# RE01_256KB register map
Vendor: Renesas Electronics Corporation; Series: RE01; File version: 1.00.01
CPU: CM0PLUS r0p1, little endian, MPU, no FPU, VTOR, 2 interrupt priority bits, 32 interrupts
Registers are 8-bit, read-write, reset 0x0 unless marked. A register's access mark holds for its fields unless they carry their own. Offsets are from the block's base; [hi:lo] are bit positions; 'fields as' and 'values as' point back to an identical list.

## MMF — Memory Mirror Function
Base 0x40001000
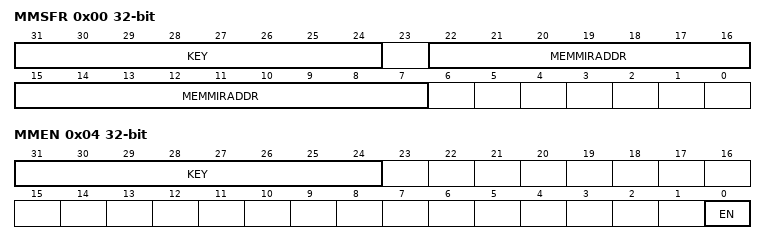
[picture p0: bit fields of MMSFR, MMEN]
0x00 MMSFR 32-bit — MemMirror Special Function Register
  [31:24] KEY wo — MMSFR Key Code
  [22:7] MEMMIRADDR — Memory Mirror Address
0x04 MMEN 32-bit — MemMirror Enable Register
  [31:24] KEY wo — MMEN Key Code
  [0] EN — Memory Mirror Function Enable
    0=Disable MMF; 1=Enable MMF

## BUS — BUS Control
Base 0x40003000
0x1008 BUSMCNTSYS 16-bit — Bus Master Control Register SYS
  [15] IERES — Ignore Error Responses
    0=A bus error is reported; 1=A bus error is not reported
0x100C BUSMCNTDMA 16-bit — Bus Master Control Register DMA
  fields as BUSMCNTSYS
0x1820 BUS3ERRADD 32-bit ro reset not defined — Bus Error Address Register 3
  [31:0] BERAD — Bus Error Address
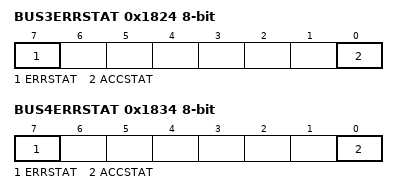
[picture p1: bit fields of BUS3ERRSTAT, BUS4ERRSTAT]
0x1824 BUS3ERRSTAT ro (reset mask 0xFE) — BUS Error Status Register 3
  [7] ERRSTAT — Bus Error Status
    0=No bus error occurred; 1=Bus error occurred
  [0] ACCSTAT — Error Access Status
    0=Read access; 1=Write access
0x1830 BUS4ERRADD 32-bit ro reset not defined — Bus Error Address Register 4
  [31:0] BERAD — Bus Error Address
0x1834 BUS4ERRSTAT ro (reset mask 0xFE) — BUS Error Status Register 4
  fields as BUS3ERRSTAT

## DMAC0 — Direct memory access controller 0
Base 0x40005000
Same registers: DMAC1 0x40005040, DMAC2 0x40005080, DMAC3 0x400050C0
0x00 DMSAR 32-bit — DMA Source Address Register
0x04 DMDAR 32-bit — DMA Destination Address Register
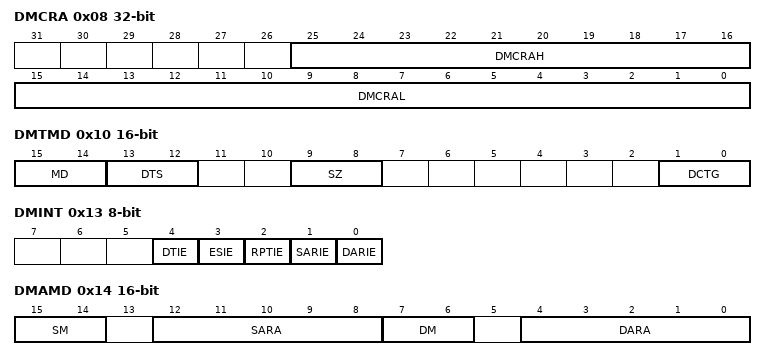
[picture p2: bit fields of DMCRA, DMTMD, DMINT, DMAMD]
0x08 DMCRA 32-bit — DMA Transfer Count Register
  [25:16] DMCRAH — Upper bits of transfer count
  [15:0] DMCRAL — Lower bits of transfer count
0x0C DMCRB 16-bit — DMA Block Transfer Count Register
0x10 DMTMD 16-bit — DMA Transfer Mode Register
  [15:14] MD — Transfer Mode Select
    0=Normal transfer; 1=Repeat transfer; 2=Block transfer; 3=Setting prohibited
  [13:12] DTS — Repeat Area Select
    0=The destination is specified as the repeat area or block area; 1=The source is specified as the repeat area or block area; 2=The repeat area or block area is not specified; 3=Setting prohibited
  [9:8] SZ — Transfer Data Size Select
    0=8 bits; 1=16 bits; 2=32 bits; 3=Setting prohibited
  [1:0] DCTG — Transfer Request Source Select
    0=Software request; 1=Hardware request; 2=Setting prohibited; 3=Setting prohibited
0x13 DMINT — DMA Interrupt Setting Register
  [4] DTIE — Transfer End Interrupt Enable
    0=Disables the transfer end interrupt request; 1=Enables the transfer end interrupt request
  [3] ESIE — Transfer Escape End Interrupt Enable
    0=Disables the transfer escape end interrupt request; 1=Enables the transfer escape end interrupt request
  [2] RPTIE — Repeat Size End Interrupt Enable
    0=Disables the repeat size end interrupt request; 1=Enables the repeat size end interrupt request
  [1] SARIE — Source Address Extended Repeat Area Overflow Interrupt Enable
    0=Disables an interrupt request for an extended repeat area overflow on the source address; 1=Enables an interrupt request for an extended repeat area overflow on the source address
  [0] DARIE — Destination Address Extended Repeat Area Overflow Interrupt Enable
    0=Disables an interrupt request for an extended repeat area overflow on the destination address; 1=Enables an interrupt request for an extended repeat area overflow on the destination address
0x14 DMAMD 16-bit — DMA Address Mode Register
  [15:14] SM — Source Address Update Mode
    0=Source address is fixed; 1=Offset addition; 2=Source address is incremented; 3=Source address is decremented
  [12:8] SARA — Source Address Extended Repeat Area
  [7:6] DM — Destination Address Update Mode
    0=Destination address is fixed; 1=Offset addition; 2=Destination address is incremented; 3=Destination address is decremented
  [4:0] DARA — Destination Address Extended Repeat Area
0x18 DMOFR 32-bit — DMA Offset Register
0x1C DMCNT — DMA Transfer Enable Register
  [0] DTE — DMA Transfer Enable
    0=Disables DMA transfer; 1=Enables DMA transfer
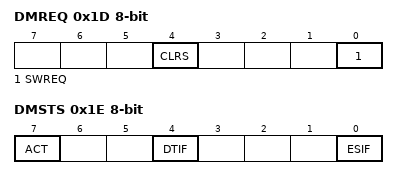
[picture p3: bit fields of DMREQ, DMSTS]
0x1D DMREQ — DMA Software Start Register
  [4] CLRS — DMA Software Start Bit Auto Clear Select
    0=SWREQ bit is cleared after DMA transfer is started by software; 1=SWREQ bit is not cleared after DMA transfer is started by software
  [0] SWREQ — DMA Software Start
    0=DMA transfer is not requested; 1=DMA transfer is requested
0x1E DMSTS — DMA Status Register
  [7] ACT ro — DMAC Active Flag
    0=DMAC is in the idle state; 1=DMAC is operating
  [4] DTIF — Transfer End Interrupt Flag
    0=A transfer end interrupt has not been generated; 1=A transfer end interrupt has been generated
  [0] ESIF — Transfer Escape End Interrupt Flag
    0=A transfer escape end interrupt has not been generated; 1=A transfer escape end interrupt has been generated
